AUTOSAR XML (schema 4.0)
package /RunnableDemo
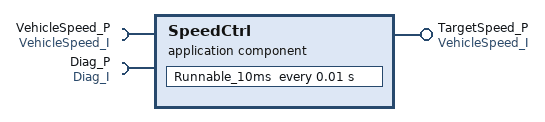
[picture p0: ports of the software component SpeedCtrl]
  application sw component type SpeedCtrl
    require port VehicleSpeed_P: required-interface=VehicleSpeed_I
    provide port TargetSpeed_P: provided-interface=VehicleSpeed_I
    require port Diag_P: required-interface=Diag_I
    behavior SpeedCtrl_Behavior
      timing event TimingEvent_10ms: start-on-event=Runnable_10ms, period=0.01
      data received event VehicleSpeedReceived: start-on-event=Runnable_OnSpeed, data-element=VehicleSpeed
      operation invoked event DiagInvoked: start-on-event=Runnable_OnDiag, operation=ReadFault
      swc mode switch event ModeChanged: start-on-event=Runnable_OnMode, on-transition=0
      init event Init: start-on-event=Runnable_Init
      6 x runnable:
        Runnable_10ms: can-enter=true, minimum-start-interval=0.01, runs-on=RTE, symbol=Rte_Runnable_SpeedCtrl_10ms
        Runnable_OnSpeed: can-enter=true, runs-on=RTE, symbol=Rte_Runnable_SpeedCtrl_OnSpeed
        Runnable_OnDiag: can-enter=false, runs-on=RTE
        Runnable_OnMode: can-enter=true, runs-on=SCHM
        Runnable_Init: can-enter=true, runs-on=RTE
        Runnable_Orphan: can-enter=true, runs-on=RTE
  application sw component type Passive
  sender receiver interface VehicleSpeed_I
    data VehicleSpeed
  client server interface Diag_I
    operation ReadFault
